VERSION "VoltBridge-ACAN-1.0"

NS_ :

BS_:

BU_: EVSE EV

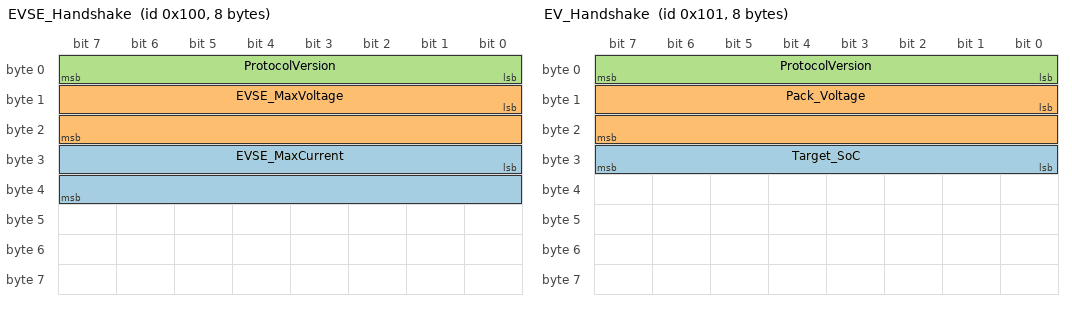
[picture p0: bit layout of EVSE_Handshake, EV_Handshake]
BO_ 256 EVSE_Handshake: 8 EVSE
 SG_ EVSE_MaxCurrent : 24|16@1+ (1,0) [0|1000] "A"  EV
 SG_ EVSE_MaxVoltage : 8|16@1+ (1,0) [0|1500] "V"  EV
 SG_ ProtocolVersion : 0|8@1+ (1,0) [0|0] ""  EV

BO_ 257 EV_Handshake: 8 EV
 SG_ Target_SoC : 24|8@1+ (1,0) [0|100] "%"  EVSE
 SG_ Pack_Voltage : 8|16@1+ (1,0) [0|1500] "V"  EVSE
 SG_ ProtocolVersion : 0|8@1+ (1,0) [0|0] ""  EVSE

BO_ 512 Insulation_Status: 8 EV
 SG_ Iso_OK : 16|8@1+ (1,0) [0|1] ""  EVSE
 SG_ Resistance : 0|16@1+ (0.1,0) [0|6553.5] "MOhm"  EVSE

BO_ 768 Precharge_Cmd: 8 EVSE
 SG_ Enable : 0|8@1+ (1,0) [0|1] ""  EV

BO_ 769 Charge_Parameters: 8 EVSE
 SG_ Limit_Current : 16|16@1+ (1,0) [0|1000] "A"  EV
 SG_ Limit_Voltage : 0|16@1+ (1,0) [0|1500] "V"  EV

BO_ 770 Charge_Request: 8 EV
 SG_ Target_Current : 16|16@1+ (1,0) [0|1000] "A"  EVSE
 SG_ Target_Voltage : 0|16@1+ (1,0) [0|1500] "V"  EVSE

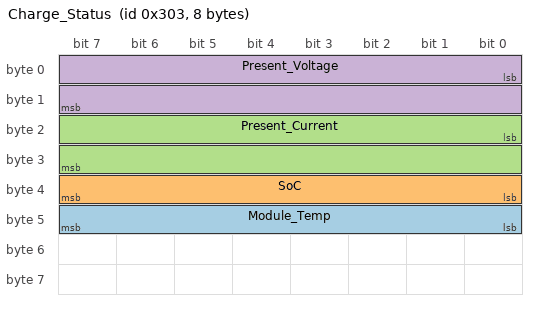
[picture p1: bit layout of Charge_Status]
BO_ 771 Charge_Status: 8 EVSE
 SG_ Module_Temp : 40|8@1+ (1,0) [0|255] "degC"  EV
 SG_ SoC : 32|8@1+ (1,0) [0|100] "%"  EV
 SG_ Present_Current : 16|16@1+ (1,0) [0|1000] "A"  EV
 SG_ Present_Voltage : 0|16@1+ (1,0) [0|1500] "V"  EV

BO_ 1024 Stop_Charge: 8 EVSE
 SG_ Reason : 0|8@1+ (1,0) [0|0] ""  EV

BO_ 2047 Emergency_Stop: 8 EVSE
 SG_ Active : 8|8@1+ (1,0) [0|1] ""  EV
 SG_ Fault_Code : 0|8@1+ (1,0) [0|0] ""  EV
